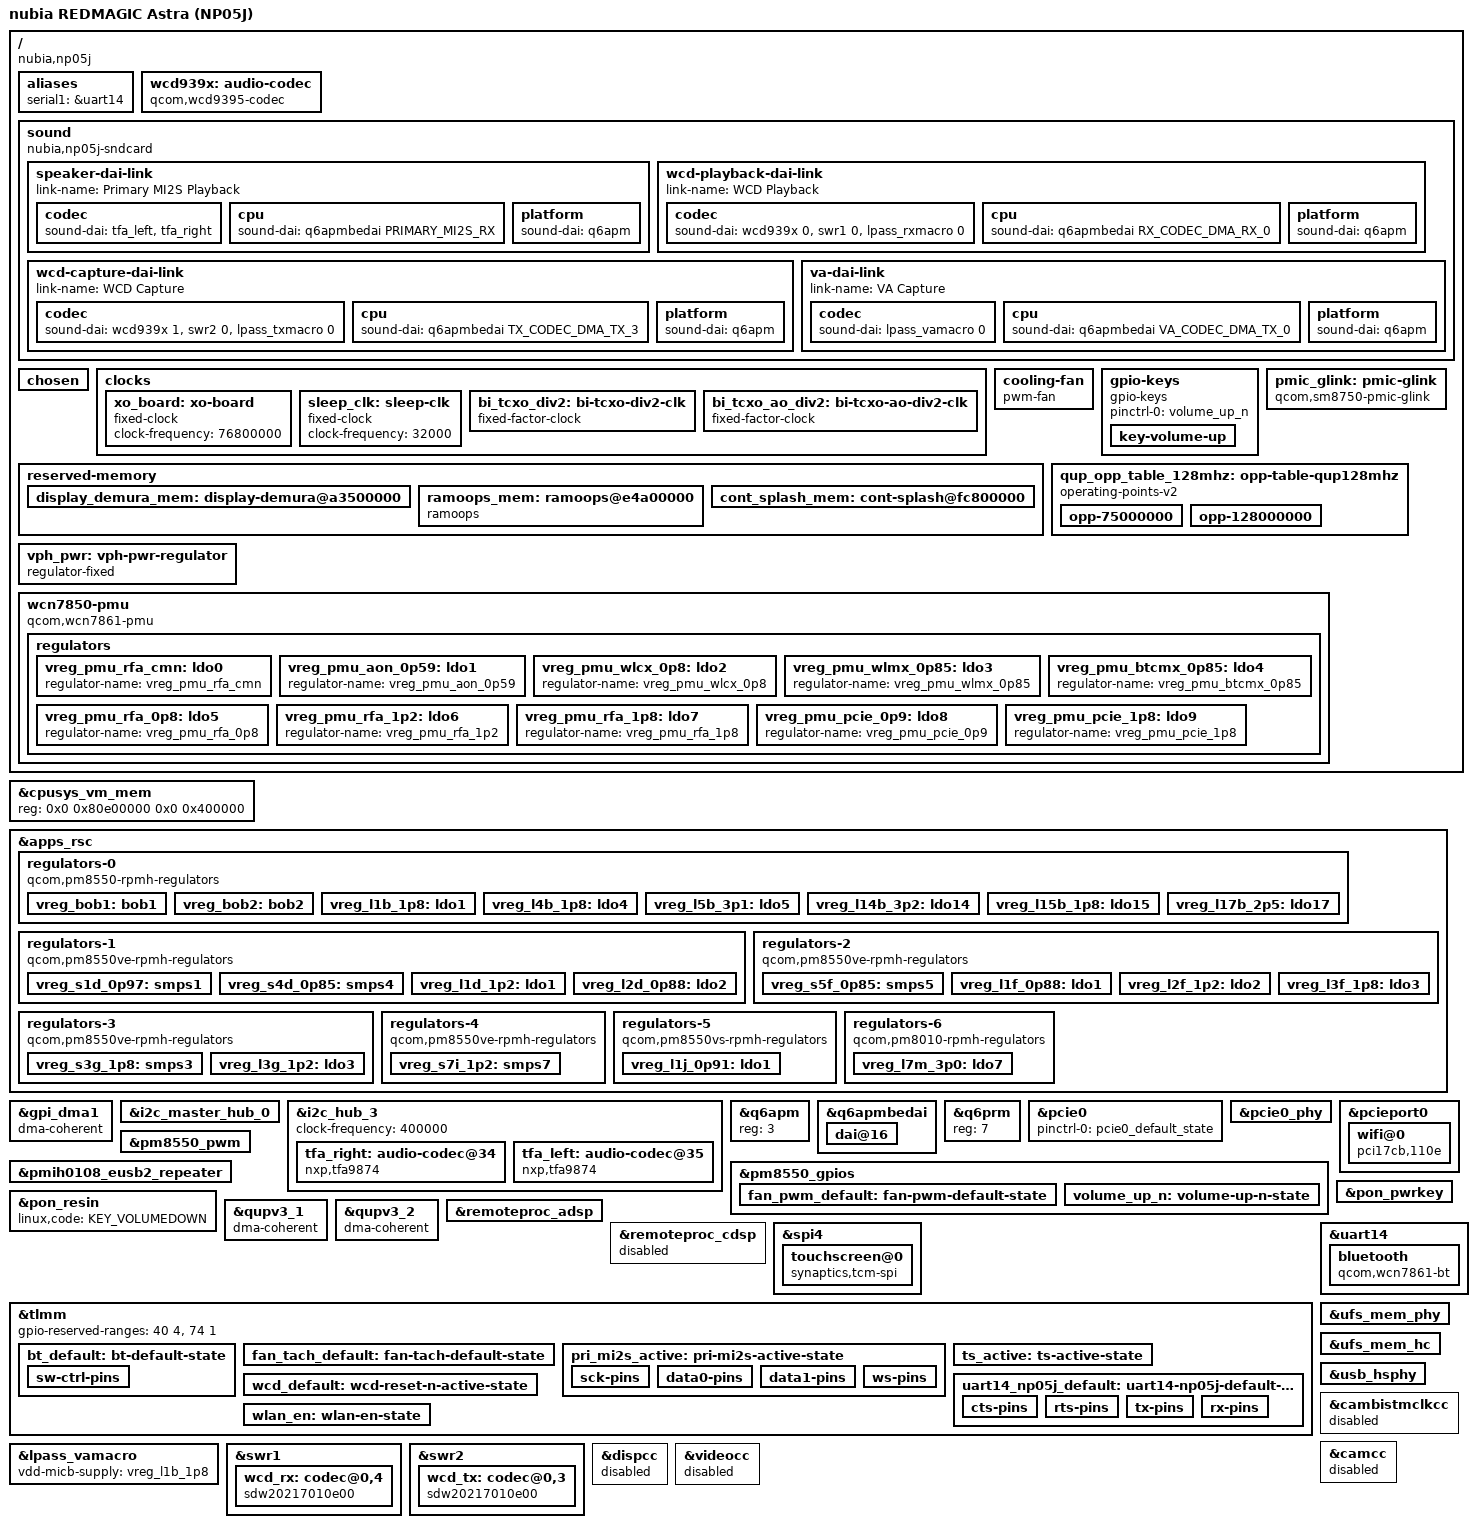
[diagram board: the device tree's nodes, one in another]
// SPDX-License-Identifier: BSD-3-Clause
/*
 * Copyright (c) 2026 Project Silicium / nubia NP05J (REDMAGIC Astra) bring-up
 *
 * Common Mainline Linux Device Tree definitions for nubia NP05J (REDMAGIC Astra),
 * Qualcomm Snapdragon 8 Elite (SM8750P / Pakala), 24 GiB LPDDR5X, 1 TB UFS 4.0.
 *
 * Verified against stock live DTB (nubia_np05j-live.dts) and upstream sm8750.dtsi.
 */

#include <dt-bindings/gpio/gpio.h>
#include <dt-bindings/input/linux-event-codes.h>
#include <dt-bindings/regulator/qcom,rpmh-regulator.h>
#include <dt-bindings/sound/qcom,q6afe.h>
#include <dt-bindings/sound/qcom,q6dsp-lpass-ports.h>
#include "sm8750.dtsi"
#include "pm8550.dtsi"
#define PMK8550VE_SID 8
#include "pm8550ve.dtsi"
#include "pmih0108.dtsi"
#include "pmk8550.dtsi"
#include "sm8750-pmics.dtsi"

/ {
	model = "nubia REDMAGIC Astra (NP05J)";
	compatible = "nubia,np05j", "qcom,sm8750";
	chassis-type = "tablet";

	aliases {
		serial1 = &uart14;
	};

	/*
	 * โคเดก WCD9395 สำหรับไมโครโฟนอะนาล็อกในตัว (AMIC1-5 ผ่าน SoundWire2 -> TX Macro)
	 * และรองรับเสียงหูฟังในอนาคต (reset gpio101, รางไฟ L15B/BOB1 ตรงตาม stock DTB)
	 */
	wcd939x: audio-codec {
		compatible = "qcom,wcd9395-codec", "qcom,wcd9390-codec";

		pinctrl-0 = <&wcd_default>;
		pinctrl-names = "default";

		qcom,micbias1-microvolt = <1800000>;
		qcom,micbias2-microvolt = <1800000>;
		qcom,micbias3-microvolt = <1800000>;
		qcom,micbias4-microvolt = <1800000>;
		qcom,mbhc-buttons-vthreshold-microvolt = <75000 150000 237000 500000 500000 500000 500000 500000>;
		qcom,mbhc-headset-vthreshold-microvolt = <1700000>;
		qcom,mbhc-headphone-vthreshold-microvolt = <50000>;
		qcom,rx-device = <&wcd_rx>;
		qcom,tx-device = <&wcd_tx>;

		reset-gpios = <&tlmm 101 GPIO_ACTIVE_LOW>;

		vdd-buck-supply = <&vreg_l15b_1p8>;
		vdd-rxtx-supply = <&vreg_l15b_1p8>;
		vdd-io-supply = <&vreg_l15b_1p8>;
		vdd-mic-bias-supply = <&vreg_bob1>;
		vdd-px-supply = <&vreg_l15b_1p8>;

		#sound-dai-cells = <1>;
	};

	/* โหนดเสียงหลัก AudioReach: ลำโพงคู่ NXP TFA9874 + ไมโครโฟนอะนาล็อก WCD9395 (AMIC) */
	sound {
		compatible = "nubia,np05j-sndcard", "qcom,sm8750-sndcard", "qcom,sm8450-sndcard";
		model = "nubia-REDMAGIC-Astra";
		pinctrl-0 = <&pri_mi2s_active>;
		pinctrl-names = "default";

		audio-routing = "IN1_HPHL", "HPHL_OUT",
				"IN2_HPHR", "HPHR_OUT",
				"AMIC1", "MIC BIAS1",
				"AMIC2", "MIC BIAS2",
				"AMIC3", "MIC BIAS3",
				"AMIC4", "MIC BIAS3",
				"AMIC5", "MIC BIAS4",
				"TX SWR_INPUT0", "ADC1_OUTPUT",
				"TX SWR_INPUT1", "ADC2_OUTPUT",
				"TX SWR_INPUT2", "ADC3_OUTPUT",
				"TX SWR_INPUT3", "ADC4_OUTPUT";

		speaker-dai-link {
			link-name = "Primary MI2S Playback";

			codec {
				sound-dai = <&tfa_left>, <&tfa_right>;
			};

			cpu {
				sound-dai = <&q6apmbedai PRIMARY_MI2S_RX>;
			};

			platform {
				sound-dai = <&q6apm>;
			};
		};

		wcd-playback-dai-link {
			link-name = "WCD Playback";

			codec {
				sound-dai = <&wcd939x 0>, <&swr1 0>, <&lpass_rxmacro 0>;
			};

			cpu {
				sound-dai = <&q6apmbedai RX_CODEC_DMA_RX_0>;
			};

			platform {
				sound-dai = <&q6apm>;
			};
		};

		wcd-capture-dai-link {
			link-name = "WCD Capture";

			codec {
				sound-dai = <&wcd939x 1>, <&swr2 0>, <&lpass_txmacro 0>;
			};

			cpu {
				sound-dai = <&q6apmbedai TX_CODEC_DMA_TX_3>;
			};

			platform {
				sound-dai = <&q6apm>;
			};
		};

		va-dai-link {
			link-name = "VA Capture";

			codec {
				sound-dai = <&lpass_vamacro 0>;
			};

			cpu {
				sound-dai = <&q6apmbedai VA_CODEC_DMA_TX_0>;
			};

			platform {
				sound-dai = <&q6apm>;
			};
		};
	};

	/* โหนด /chosen สำหรับ EFI_DT_FIXUP_PROTOCOL ของ SunUEFI และ bootargs ของ systemd-boot */
	chosen { };

	clocks {
		xo_board: xo-board {
			compatible = "fixed-clock";
			clock-frequency = <76800000>;
			#clock-cells = <0>;
		};

		sleep_clk: sleep-clk {
			compatible = "fixed-clock";
			clock-frequency = <32000>;
			#clock-cells = <0>;
		};

		bi_tcxo_div2: bi-tcxo-div2-clk {
			compatible = "fixed-factor-clock";
			#clock-cells = <0>;

			clocks = <&rpmhcc RPMH_CXO_CLK>;
			clock-mult = <1>;
			clock-div = <2>;
		};

		bi_tcxo_ao_div2: bi-tcxo-ao-div2-clk {
			compatible = "fixed-factor-clock";
			#clock-cells = <0>;

			clocks = <&rpmhcc RPMH_CXO_CLK_A>;
			clock-mult = <1>;
			clock-div = <2>;
		};
	};

	cooling-fan {
		compatible = "pwm-fan";
		pwms = <&pm8550_pwm 3 40000>;
		fan-supply = <&vreg_l7m_3p0>;
		interrupts-extended = <&tlmm 183 IRQ_TYPE_EDGE_FALLING>;
		pulses-per-revolution = <2>;
		cooling-levels = <0 64 128 192 255>;
		pinctrl-names = "default";
		pinctrl-0 = <&fan_pwm_default>, <&fan_tach_default>;
		#cooling-cells = <2>;
	};

	gpio-keys {
		compatible = "gpio-keys";

		pinctrl-0 = <&volume_up_n>;
		pinctrl-names = "default";

		key-volume-up {
			label = "Volume Up";
			linux,code = <KEY_VOLUMEUP>;
			gpios = <&pm8550_gpios 6 GPIO_ACTIVE_LOW>;
			debounce-interval = <15>;
			linux,can-disable;
			wakeup-source;
		};
	};

	pmic_glink: pmic-glink {
		compatible = "qcom,sm8750-pmic-glink",
			     "qcom,sm8550-pmic-glink",
			     "qcom,pmic-glink";
		#address-cells = <1>;
		#size-cells = <0>;
	};

	reserved-memory {
		display_demura_mem: display-demura@a3500000 {
			reg = <0x0 0xa3500000 0x0 0x2c80000>;
			no-map;
		};

		ramoops_mem: ramoops@e4a00000 {
			compatible = "ramoops";
			reg = <0x0 0xe4a00000 0x0 0x200000>;
			console-size = <0x200000>;
			no-map;
		};

		cont_splash_mem: cont-splash@fc800000 {
			reg = <0x0 0xfc800000 0x0 0x2b00000>;
			no-map;
		};
	};

	qup_opp_table_128mhz: opp-table-qup128mhz {
		compatible = "operating-points-v2";

		opp-75000000 {
			opp-hz = /bits/ 64 <75000000>;
			required-opps = <&rpmhpd_opp_low_svs>;
		};

		opp-128000000 {
			opp-hz = /bits/ 64 <128000000>;
			required-opps = <&rpmhpd_opp_svs>;
		};
	};

	vph_pwr: vph-pwr-regulator {
		compatible = "regulator-fixed";

		regulator-name = "vph_pwr";
		regulator-min-microvolt = <3700000>;
		regulator-max-microvolt = <3700000>;

		regulator-always-on;
		regulator-boot-on;
	};

	/*
	 * FastConnect 7900 ("Peach" / WCN7861) PMU power sequencing + OL-CPR PDC maps.
	 * ยืนยันจาก stock live DTB (vendor/np05j/dtb/np05j.dtb qcom,cnss-peach@b0000000):
	 * wlan-en=tlmm 16, bt-en=pm8550ve_f_gpios 3, sw-ctrl=tlmm 18, RF_CLK1,
	 * vdd/vdddig=S5F, vddaon=S4D, vddio=L3F, vddio1p2=L2F, rfa1p2=S7I, rfa1p8=S3G.
	 */
	wcn7850-pmu {
		compatible = "qcom,wcn7861-pmu";

		pinctrl-names = "default";
		pinctrl-0 = <&wlan_en>, <&bt_default>;

		wlan-enable-gpios = <&tlmm 16 GPIO_ACTIVE_HIGH>;
		bt-enable-gpios = <&pm8550ve_f_gpios 3 GPIO_ACTIVE_HIGH>;

		vdd-supply = <&vreg_s5f_0p85>;
		vddio-supply = <&vreg_l3f_1p8>;
		vddio1p2-supply = <&vreg_l2f_1p2>;
		vddaon-supply = <&vreg_s4d_0p85>;
		vdddig-supply = <&vreg_s5f_0p85>;
		vddrfa1p2-supply = <&vreg_s7i_1p2>;
		vddrfa1p8-supply = <&vreg_s3g_1p8>;

		clocks = <&rpmhcc RPMH_RF_CLK1>;
		qcom,qmp = <&aoss_qmp>;

		qcom,pdc-init-table =
			"{class: wlan_pdc, ss: rf, res: s5f.m, enable: 1}",
			"{class: wlan_pdc, ss: rf, res: s5f.v, enable: 1}",
			"{class: wlan_pdc, ss: rf, res: s5f.v, upval: 876}",
			"{class: wlan_pdc, ss: rf, res: s5f.v, dwnval: 876}";
		qcom,vreg-pdc-map =
			"s5f:rf",
			"s4d:bb",
			"s3g:rf",
			"s7i:rf";
		qcom,pmu-vreg-map =
			"VDDD_AON_0P9:s5f",
			"VDDA_RFA_1P9:s3g",
			"VDDA_RFA_1P3:s7i",
			"VDDA_RFA_0P9:s5f",
			"VDDD_WLMX_0P9:s4d",
			"VDDD_WLCX_0P9:s5f",
			"VDDD_BTCX_0P9:s5f",
			"VDDD_BTCMX_0P9:s5f",
			"VDDA_PCIE_1P2:s7i",
			"VDDA_PCIE_0P9:s7i";

		regulators {
			vreg_pmu_rfa_cmn: ldo0 {
				regulator-name = "vreg_pmu_rfa_cmn";
			};

			vreg_pmu_aon_0p59: ldo1 {
				regulator-name = "vreg_pmu_aon_0p59";
			};

			vreg_pmu_wlcx_0p8: ldo2 {
				regulator-name = "vreg_pmu_wlcx_0p8";
			};

			vreg_pmu_wlmx_0p85: ldo3 {
				regulator-name = "vreg_pmu_wlmx_0p85";
			};

			vreg_pmu_btcmx_0p85: ldo4 {
				regulator-name = "vreg_pmu_btcmx_0p85";
			};

			vreg_pmu_rfa_0p8: ldo5 {
				regulator-name = "vreg_pmu_rfa_0p8";
			};

			vreg_pmu_rfa_1p2: ldo6 {
				regulator-name = "vreg_pmu_rfa_1p2";
			};

			vreg_pmu_rfa_1p8: ldo7 {
				regulator-name = "vreg_pmu_rfa_1p8";
			};

			vreg_pmu_pcie_0p9: ldo8 {
				regulator-name = "vreg_pmu_pcie_0p9";
			};

			vreg_pmu_pcie_1p8: ldo9 {
				regulator-name = "vreg_pmu_pcie_1p8";
			};
		};
	};
};

/* Match NP05J stock 4 MiB cpusys_vm reservation (0x80e00000..0x81200000) */
&cpusys_vm_mem {
	reg = <0x0 0x80e00000 0x0 0x400000>;
};

/*
 * Safe RPMh regulator subset for UFS 4.0, USB-C, PCIe0/Wi-Fi 7, Bluetooth,
 * and SPI4 Touchscreen. Shared bucks and touch/IO rails are kept boot-on +
 * always-on so active OLED panel rails are never powered down.
 */
&apps_rsc {
	regulators-0 {
		compatible = "qcom,pm8550-rpmh-regulators";

		vdd-bob1-supply = <&vph_pwr>;
		vdd-bob2-supply = <&vph_pwr>;
		vdd-l1-l4-l10-supply = <&vreg_s3g_1p8>;
		vdd-l2-l13-l14-supply = <&vreg_bob1>;
		vdd-l5-l16-supply = <&vreg_bob1>;
		vdd-l15-supply = <&vreg_s3g_1p8>;
		vdd-l17-supply = <&vreg_bob2>;

		qcom,pmic-id = "b";

		vreg_bob1: bob1 {
			regulator-name = "vreg_bob1";
			regulator-min-microvolt = <3008000>;
			regulator-max-microvolt = <4000000>;
			regulator-initial-mode = <RPMH_REGULATOR_MODE_HPM>;
			regulator-always-on;
			regulator-boot-on;
		};

		vreg_bob2: bob2 {
			regulator-name = "vreg_bob2";
			regulator-min-microvolt = <2704000>;
			regulator-max-microvolt = <3008000>;
			regulator-initial-mode = <RPMH_REGULATOR_MODE_HPM>;
			regulator-always-on;
			regulator-boot-on;
		};

		vreg_l1b_1p8: ldo1 {
			regulator-name = "vreg_l1b_1p8";
			regulator-min-microvolt = <1800000>;
			regulator-max-microvolt = <1800000>;
			regulator-initial-mode = <RPMH_REGULATOR_MODE_HPM>;
			regulator-allow-set-load;
			regulator-allowed-modes = <RPMH_REGULATOR_MODE_LPM
						   RPMH_REGULATOR_MODE_HPM>;
		};

		vreg_l4b_1p8: ldo4 {
			regulator-name = "vreg_l4b_1p8";
			regulator-min-microvolt = <1800000>;
			regulator-max-microvolt = <1800000>;
			regulator-initial-mode = <RPMH_REGULATOR_MODE_HPM>;
			regulator-allow-set-load;
			regulator-allowed-modes = <RPMH_REGULATOR_MODE_LPM
						   RPMH_REGULATOR_MODE_HPM>;
			regulator-always-on;
			regulator-boot-on;
		};

		vreg_l5b_3p1: ldo5 {
			regulator-name = "vreg_l5b_3p1";
			regulator-min-microvolt = <3100000>;
			regulator-max-microvolt = <3148000>;
			regulator-initial-mode = <RPMH_REGULATOR_MODE_HPM>;
			regulator-allow-set-load;
			regulator-allowed-modes = <RPMH_REGULATOR_MODE_LPM
						   RPMH_REGULATOR_MODE_HPM>;
		};

		vreg_l14b_3p2: ldo14 {
			regulator-name = "vreg_l14b_3p2";
			regulator-min-microvolt = <3200000>;
			regulator-max-microvolt = <3200000>;
			regulator-initial-mode = <RPMH_REGULATOR_MODE_HPM>;
			regulator-allow-set-load;
			regulator-allowed-modes = <RPMH_REGULATOR_MODE_LPM
						   RPMH_REGULATOR_MODE_HPM>;
			regulator-always-on;
			regulator-boot-on;
		};

		vreg_l15b_1p8: ldo15 {
			regulator-name = "vreg_l15b_1p8";
			regulator-min-microvolt = <1800000>;
			regulator-max-microvolt = <1800000>;
			regulator-initial-mode = <RPMH_REGULATOR_MODE_HPM>;
			regulator-allow-set-load;
			regulator-allowed-modes = <RPMH_REGULATOR_MODE_LPM
						   RPMH_REGULATOR_MODE_HPM>;
			regulator-always-on;
			regulator-boot-on;
		};

		vreg_l17b_2p5: ldo17 {
			regulator-name = "vreg_l17b_2p5";
			regulator-min-microvolt = <2504000>;
			regulator-max-microvolt = <2504000>;
			regulator-initial-mode = <RPMH_REGULATOR_MODE_HPM>;
			regulator-allow-set-load;
			regulator-allowed-modes = <RPMH_REGULATOR_MODE_LPM
						   RPMH_REGULATOR_MODE_HPM>;
		};
	};

	regulators-1 {
		compatible = "qcom,pm8550ve-rpmh-regulators";

		vdd-l1-supply = <&vreg_s7i_1p2>;
		vdd-l2-supply = <&vreg_s1d_0p97>;
		vdd-s1-supply = <&vph_pwr>;
		vdd-s4-supply = <&vph_pwr>;

		qcom,pmic-id = "d";

		vreg_s1d_0p97: smps1 {
			regulator-name = "vreg_s1d_0p97";
			regulator-min-microvolt = <880000>;
			regulator-max-microvolt = <1100000>;
			regulator-initial-mode = <RPMH_REGULATOR_MODE_HPM>;
			regulator-always-on;
			regulator-boot-on;
		};

		vreg_s4d_0p85: smps4 {
			regulator-name = "vreg_s4d_0p85";
			regulator-min-microvolt = <852000>;
			regulator-max-microvolt = <1036000>;
			regulator-initial-mode = <RPMH_REGULATOR_MODE_HPM>;
			regulator-always-on;
			regulator-boot-on;
		};

		vreg_l1d_1p2: ldo1 {
			regulator-name = "vreg_l1d_1p2";
			regulator-min-microvolt = <1200000>;
			regulator-max-microvolt = <1200000>;
			regulator-initial-mode = <RPMH_REGULATOR_MODE_HPM>;
			regulator-allow-set-load;
			regulator-allowed-modes = <RPMH_REGULATOR_MODE_LPM
						   RPMH_REGULATOR_MODE_HPM>;
		};

		vreg_l2d_0p88: ldo2 {
			regulator-name = "vreg_l2d_0p88";
			regulator-min-microvolt = <880000>;
			regulator-max-microvolt = <912000>;
			regulator-initial-mode = <RPMH_REGULATOR_MODE_HPM>;
			regulator-allow-set-load;
			regulator-allowed-modes = <RPMH_REGULATOR_MODE_LPM
						   RPMH_REGULATOR_MODE_HPM>;
		};
	};

	regulators-2 {
		compatible = "qcom,pm8550ve-rpmh-regulators";

		vdd-l1-supply = <&vreg_s1d_0p97>;
		vdd-l2-supply = <&vreg_s7i_1p2>;
		vdd-l3-supply = <&vreg_s3g_1p8>;
		vdd-s5-supply = <&vph_pwr>;

		qcom,pmic-id = "f";

		vreg_s5f_0p85: smps5 {
			regulator-name = "vreg_s5f_0p85";
			regulator-min-microvolt = <852000>;
			regulator-max-microvolt = <1000000>;
			regulator-initial-mode = <RPMH_REGULATOR_MODE_HPM>;
			regulator-always-on;
			regulator-boot-on;
		};

		vreg_l1f_0p88: ldo1 {
			regulator-name = "vreg_l1f_0p88";
			regulator-min-microvolt = <880000>;
			regulator-max-microvolt = <920000>;
			regulator-initial-mode = <RPMH_REGULATOR_MODE_HPM>;
			regulator-allow-set-load;
			regulator-allowed-modes = <RPMH_REGULATOR_MODE_LPM
						   RPMH_REGULATOR_MODE_HPM>;
		};

		vreg_l2f_1p2: ldo2 {
			regulator-name = "vreg_l2f_1p2";
			regulator-min-microvolt = <1200000>;
			regulator-max-microvolt = <1200000>;
			regulator-initial-mode = <RPMH_REGULATOR_MODE_HPM>;
			regulator-allow-set-load;
			regulator-allowed-modes = <RPMH_REGULATOR_MODE_LPM
						   RPMH_REGULATOR_MODE_HPM>;
		};

		vreg_l3f_1p8: ldo3 {
			regulator-name = "vreg_l3f_1p8";
			regulator-min-microvolt = <1800000>;
			regulator-max-microvolt = <1800000>;
			regulator-initial-mode = <RPMH_REGULATOR_MODE_HPM>;
			regulator-allow-set-load;
			regulator-allowed-modes = <RPMH_REGULATOR_MODE_LPM
						   RPMH_REGULATOR_MODE_HPM>;
		};
	};

	regulators-3 {
		compatible = "qcom,pm8550ve-rpmh-regulators";

		vdd-l3-supply = <&vreg_s7i_1p2>;
		vdd-s3-supply = <&vph_pwr>;

		qcom,pmic-id = "g";

		vreg_s3g_1p8: smps3 {
			regulator-name = "vreg_s3g_1p8";
			regulator-min-microvolt = <1856000>;
			regulator-max-microvolt = <2000000>;
			regulator-initial-mode = <RPMH_REGULATOR_MODE_HPM>;
			regulator-allow-set-load;
			regulator-allowed-modes = <RPMH_REGULATOR_MODE_LPM
						   RPMH_REGULATOR_MODE_HPM>;
			regulator-always-on;
			regulator-boot-on;
		};

		vreg_l3g_1p2: ldo3 {
			regulator-name = "vreg_l3g_1p2";
			regulator-min-microvolt = <1200000>;
			regulator-max-microvolt = <1256000>;
			regulator-initial-mode = <RPMH_REGULATOR_MODE_HPM>;
			regulator-allow-set-load;
			regulator-allowed-modes = <RPMH_REGULATOR_MODE_LPM
						   RPMH_REGULATOR_MODE_HPM>;
		};
	};

	regulators-4 {
		compatible = "qcom,pm8550ve-rpmh-regulators";

		vdd-s7-supply = <&vph_pwr>;

		qcom,pmic-id = "i";

		vreg_s7i_1p2: smps7 {
			regulator-name = "vreg_s7i_1p2";
			regulator-min-microvolt = <1224000>;
			regulator-max-microvolt = <1340000>;
			regulator-initial-mode = <RPMH_REGULATOR_MODE_HPM>;
			regulator-always-on;
			regulator-boot-on;
		};
	};

	regulators-5 {
		compatible = "qcom,pm8550vs-rpmh-regulators";

		vdd-l1-supply = <&vreg_s1d_0p97>;

		qcom,pmic-id = "j";

		vreg_l1j_0p91: ldo1 {
			regulator-name = "vreg_l1j_0p91";
			regulator-min-microvolt = <880000>;
			regulator-max-microvolt = <920000>;
			regulator-initial-mode = <RPMH_REGULATOR_MODE_HPM>;
			regulator-allow-set-load;
			regulator-allowed-modes = <RPMH_REGULATOR_MODE_LPM
						   RPMH_REGULATOR_MODE_HPM>;
		};
	};

	regulators-6 {
		compatible = "qcom,pm8010-rpmh-regulators";

		vdd-l7-supply = <&vreg_bob1>;

		qcom,pmic-id = "m";

		vreg_l7m_3p0: ldo7 {
			regulator-name = "vreg_l7m_3p0";
			regulator-min-microvolt = <2800000>;
			regulator-max-microvolt = <3000000>;
			regulator-initial-mode = <RPMH_REGULATOR_MODE_HPM>;
		};
	};
};

&gpi_dma1 {
	dma-coherent;
	status = "okay";
};

&i2c_master_hub_0 {
	status = "okay";
};

/* Dual NXP TFA9874 stereo smart amps (@0x34 Right, @0x35 Left) + AW22xxx RGB LED (@0x6a) */
&i2c_hub_3 {
	clock-frequency = <400000>;
	status = "okay";

	tfa_right: audio-codec@34 {
		compatible = "nxp,tfa9874";
		reg = <0x34>;
		#sound-dai-cells = <0>;
		firmware-name = "tfa98xx.cnt";
		sound-name-prefix = "SpkrRight";
	};

	tfa_left: audio-codec@35 {
		compatible = "nxp,tfa9874";
		reg = <0x35>;
		#sound-dai-cells = <0>;
		firmware-name = "tfa98xx.cnt";
		sound-name-prefix = "SpkrLeft";
	};
};

/*
 * เฟิร์มแวร์ ADSP บน SM8750 รับคำสั่งผ่านพอร์ต GPR แบบสแตติกเฉพาะพอร์ต 3 (APM) และ 7 (PRM)
 * (ตรงตาม dtbo-piano-audio.dts) และกำหนดนาฬิกา bclk ของ Primary MI2S สำหรับแอมป์ TFA9874
 */
&q6apm {
	reg = <3>;
};

&q6apmbedai {
	#address-cells = <1>;
	#size-cells = <0>;

	dai@16 {
		reg = <PRIMARY_MI2S_RX>;
		clocks = <&q6prmcc LPASS_CLK_ID_PRI_MI2S_IBIT LPASS_CLK_ATTRIBUTE_COUPLE_NO>;
		clock-names = "bclk";
	};
};

&q6prm {
	reg = <7>;
};

&pcie0 {
	pinctrl-0 = <&pcie0_default_state>;
	pinctrl-names = "default";

	status = "okay";
};

&pcie0_phy {
	vdda-phy-supply = <&vreg_l1f_0p88>;
	vdda-pll-supply = <&vreg_l3g_1p2>;

	status = "okay";
};

&pcieport0 {
	wake-gpios = <&tlmm 104 GPIO_ACTIVE_HIGH>;
	reset-gpios = <&tlmm 102 GPIO_ACTIVE_LOW>;

	wifi@0 {
		compatible = "pci17cb,110e", "pci17cb,1107";
		reg = <0x10000 0x0 0x0 0x0 0x0>;

		vddrfacmn-supply = <&vreg_pmu_rfa_cmn>;
		vddaon-supply = <&vreg_pmu_aon_0p59>;
		vddwlcx-supply = <&vreg_pmu_wlcx_0p8>;
		vddwlmx-supply = <&vreg_pmu_wlmx_0p85>;
		vddrfa0p8-supply = <&vreg_pmu_rfa_0p8>;
		vddrfa1p2-supply = <&vreg_pmu_rfa_1p2>;
		vddrfa1p8-supply = <&vreg_pmu_rfa_1p8>;
		vddpcie0p9-supply = <&vreg_pmu_pcie_0p9>;
		vddpcie1p8-supply = <&vreg_pmu_pcie_1p8>;
	};
};

&pm8550_gpios {
	fan_pwm_default: fan-pwm-default-state {
		pins = "gpio9";
		function = "func1";
		bias-disable;
		output-enable;
		power-source = <0>;
	};

	volume_up_n: volume-up-n-state {
		pins = "gpio6";
		function = "normal";
		bias-pull-up;
		input-enable;
		power-source = <1>;
	};
};

&pm8550_pwm {
	status = "okay";
};

/* Live DT: qcom,param-override-seq = <0x0a 0x51 0x02 0x53> */
&pmih0108_eusb2_repeater {
	qcom,tune-usb2-amplitude = /bits/ 8 <0xa>;
	qcom,tune-usb2-disc-thres = /bits/ 8 <0x2>;

	vdd18-supply = <&vreg_l15b_1p8>;
	vdd3-supply = <&vreg_l5b_3p1>;

	status = "okay";
};

&pon_pwrkey {
	status = "okay";
};

&pon_resin {
	linux,code = <KEY_VOLUMEDOWN>;
	status = "okay";
};

&qupv3_1 {
	dma-coherent;
	status = "okay";
};

&qupv3_2 {
	dma-coherent;
	status = "okay";
};

/*
 * เปิด ADSP remoteproc พร้อม qcom,no-auto-boot เพื่อไม่ให้เริ่มบูตตอน initramfs
 * ก่อนเฟิร์มแวร์บน rootfs พร้อม แล้วให้ np05j-fw-load สั่งเริ่มงานจาก userspace
 * เพื่อปลดล็อก pmic-glink (USB-C OTG 5V VBUS / Role Switch และสถานะแบตเตอรี่);
 * คง CDSP ปิดไว้ก่อนจนกว่าจะทดสอบแยกต่างหาก
 */
&remoteproc_adsp {
	firmware-name = "qcom/sm8750/adsp.mdt",
			"qcom/sm8750/adsp_dtb.mdt";
	qcom,no-auto-boot;

	status = "okay";
};

&remoteproc_cdsp {
	firmware-name = "qcom/sm8750/cdsp.mdt",
			"qcom/sm8750/cdsp_dtb.mdt";

	status = "disabled";
};

/*
 * Touchscreen SPI4 bus (QUPv3 Wrap1 SE4 @ 0xa90000, GPIOs 48..51, GPI DMA1).
 * Verified live hardware: Synaptics S3930TB0A0 (TCM v2, 15039x23999, 10-finger)
 * on CS0, Reset = tlmm 161, IRQ = tlmm 162, avdd = L14B (3.2V), vdd = L4B (1.8V).
 */
&spi4 {
	status = "okay";

	touchscreen@0 {
		compatible = "synaptics,tcm-spi";
		reg = <0>;
		spi-max-frequency = <5000000>;

		reset-gpios = <&tlmm 161 GPIO_ACTIVE_LOW>;
		interrupts-extended = <&tlmm 162 IRQ_TYPE_LEVEL_LOW>;

		vdd-supply = <&vreg_l4b_1p8>;
		avdd-supply = <&vreg_l14b_3p2>;

		pinctrl-names = "default";
		pinctrl-0 = <&ts_active>;
	};
};

/* Live DT: qcom,gpios-reserved = <0x28 0x29 0x2a 0x2b 0x4a> (GPIOs 40-43, 74) */
&tlmm {
	gpio-reserved-ranges = <40 4>, <74 1>;

	bt_default: bt-default-state {
		sw-ctrl-pins {
			pins = "gpio18";
			function = "gpio";
			bias-pull-down;
		};
	};

	fan_tach_default: fan-tach-default-state {
		pins = "gpio183";
		function = "gpio";
		drive-strength = <16>;
		bias-pull-up;
		input-enable;
	};

	/* Primary MI2S (i2s0) สำหรับแอมป์ลำโพงคู่ NXP TFA9874 ตรงตาม stock pri_mi2s_pinctrl */
	pri_mi2s_active: pri-mi2s-active-state {
		sck-pins {
			pins = "gpio126";
			function = "i2s0_sck";
			drive-strength = <8>;
			bias-disable;
		};

		data0-pins {
			pins = "gpio127";
			function = "i2s0_data0";
			drive-strength = <8>;
			bias-disable;
		};

		data1-pins {
			pins = "gpio128";
			function = "i2s0_data1";
			drive-strength = <8>;
			bias-disable;
		};

		ws-pins {
			pins = "gpio129";
			function = "i2s0_ws";
			drive-strength = <8>;
			bias-disable;
		};
	};

	ts_active: ts-active-state {
		pins = "gpio161", "gpio162";
		function = "gpio";
		drive-strength = <8>;
		bias-pull-up;
	};

	uart14_np05j_default: uart14-np05j-default-state {
		cts-pins {
			pins = "gpio24";
			function = "qup2_se6";
			drive-strength = <2>;
			bias-disable;
		};

		rts-pins {
			pins = "gpio25";
			function = "qup2_se6";
			drive-strength = <2>;
			bias-pull-down;
		};

		tx-pins {
			pins = "gpio26";
			function = "qup2_se6";
			drive-strength = <2>;
			bias-pull-up;
		};

		rx-pins {
			pins = "gpio27";
			function = "qup2_se6";
			drive-strength = <2>;
			bias-disable;
		};
	};

	wcd_default: wcd-reset-n-active-state {
		pins = "gpio101";
		function = "gpio";
		drive-strength = <16>;
		bias-disable;
		output-low;
	};

	wlan_en: wlan-en-state {
		pins = "gpio16";
		function = "gpio";
		drive-strength = <8>;
		bias-pull-down;
	};
};

&lpass_vamacro {
	vdd-micb-supply = <&vreg_l1b_1p8>;
};

&swr1 {
	status = "okay";

	/* WCD9395 RX */
	wcd_rx: codec@0,4 {
		compatible = "sdw20217010e00";
		reg = <0 4>;
		qcom,rx-port-mapping = <1 2 3 4 5 9>;
	};
};

&swr2 {
	status = "okay";

	/* WCD9395 TX */
	wcd_tx: codec@0,3 {
		compatible = "sdw20217010e00";
		reg = <0 3>;
		qcom,tx-port-mapping = <2 2 3 4>;
	};
};

/*
 * Bluetooth UART14 (QUPv3 Wrap2 SE6 @ 0x898000, FastConnect 7900 / BRAHMA 2.0).
 * Restore 4-wire CTS/RTS (gpio24/25) with exact live-DT bias, CX OPP table
 * for 51.2 MHz (3.2 Mbps), and qup-memory ICC for GENI_SE_DMA.
 */
&uart14 {
	interconnects = <&clk_virt MASTER_QUP_CORE_2 QCOM_ICC_TAG_ALWAYS
			 &clk_virt SLAVE_QUP_CORE_2 QCOM_ICC_TAG_ALWAYS>,
			<&gem_noc MASTER_APPSS_PROC QCOM_ICC_TAG_ALWAYS
			 &config_noc SLAVE_QUP_2 QCOM_ICC_TAG_ALWAYS>,
			<&aggre2_noc MASTER_QUP_2 QCOM_ICC_TAG_ALWAYS
			 &mc_virt SLAVE_EBI1 QCOM_ICC_TAG_ALWAYS>;
	interconnect-names = "qup-core", "qup-config", "qup-memory";

	power-domains = <&rpmhpd RPMHPD_CX>;
	operating-points-v2 = <&qup_opp_table_128mhz>;

	pinctrl-0 = <&qup_uart14_default>, <&qup_uart14_cts_rts>;
	pinctrl-names = "default";
	status = "okay";

	bluetooth {
		compatible = "qcom,wcn7861-bt";

		vddrfacmn-supply = <&vreg_pmu_rfa_cmn>;
		vddaon-supply = <&vreg_pmu_aon_0p59>;
		vddwlcx-supply = <&vreg_pmu_wlcx_0p8>;
		vddwlmx-supply = <&vreg_pmu_wlmx_0p85>;
		vddrfa0p8-supply = <&vreg_pmu_rfa_0p8>;
		vddrfa1p2-supply = <&vreg_pmu_rfa_1p2>;
		vddrfa1p8-supply = <&vreg_pmu_rfa_1p8>;

		max-speed = <3200000>;
		/*
		 * ที่อยู่ MAC แท้จริงอยู่ในพาร์ติชัน persist ของ Android; กำหนดค่า locally administered
		 * (02:4E:50:30:35:4A, "NP05J", little-endian) เพื่อไม่ให้ hci_qca ล็อก hci0 ไว้ในโหมด RAW
		 */
		local-bd-address = [4a 35 30 50 4e 02];
	};
};

&ufs_mem_phy {
	vdda-phy-supply = <&vreg_l1j_0p91>;
	vdda-pll-supply = <&vreg_l3g_1p2>;

	status = "okay";
};

&ufs_mem_hc {
	reset-gpios = <&tlmm 215 GPIO_ACTIVE_LOW>;

	vcc-supply = <&vreg_l17b_2p5>;
	vcc-max-microamp = <1300000>;
	vccq-supply = <&vreg_l1d_1p2>;
	vccq-max-microamp = <1200000>;

	status = "okay";
};

&usb_hsphy {
	vdd-supply = <&vreg_l2d_0p88>;
	vdda12-supply = <&vreg_l3g_1p2>;

	phys = <&pmih0108_eusb2_repeater>;

	status = "okay";
};

/*
 * ปิด clock controller กลุ่ม multimedia (MMCX) ระหว่างใช้ UEFI GOP / simpledrm:
 * dispcc-sm8750 จะตั้งค่า PLL0/1/2 ใหม่และปล่อยโหวต RPMHPD_MMCX ขณะ probe
 * ทำให้สัญญาณจอ OLED continuous splash หยุดกลางเฟรมทันทีที่ udev โหลดโมดูล
 */
&cambistmclkcc {
	status = "disabled";
};

&camcc {
	status = "disabled";
};

&dispcc {
	status = "disabled";
};

&videocc {
	status = "disabled";
};
